AUTOSAR XML (schema 4-2-2)
package /Components
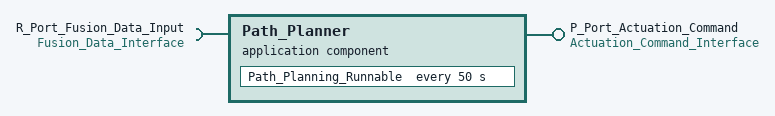
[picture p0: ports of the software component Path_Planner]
  application sw component type Path_Planner
    provide port P_Port_Actuation_Command: provided-interface=Actuation_Command_Interface
    require port R_Port_Fusion_Data_Input: required-interface=Fusion_Data_Interface
    behavior Path_Planner_Internal_Behavior
      data send completed event Plan_Sent: start-on-event=Path_Planning_Runnable
      timing event Planner_Tick: start-on-event=Path_Planning_Runnable, period=50
      runnable Path_Planning_Runnable: symbol=Path_Planning_Symbol
        data-receive-point-by-arguments:
          access Fusion_Data_Input: accessed-variable=R_Port_Fusion_Data_Input.Fused_Data
        data-send-points:
          access Actuation_Command_Output: accessed-variable=P_Port_Actuation_Command.Actuation_Command
